# ISD9100_v3 register map
File version: 1.0
Registers are 32-bit, read-write, reset 0x0 unless marked. A register's access mark holds for its fields unless they carry their own. Offsets are from the block's base; [hi:lo] are bit positions.

## WDT — WDT Register Map
Base 0x40004000
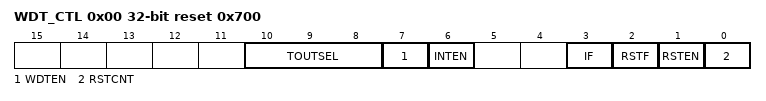
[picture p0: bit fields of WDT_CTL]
0x00 WDT_CTL reset 0x700 — Watchdog Timer Control Register
  [10:8] TOUTSEL — Watchdog Timer Interval Select. These three bits select the timeout interval for the Watchdog timer, a watchdog reset will occur 1024 clock cycles later if WDG not reset. The timeout is given by: Interrupt Timeout aaa 2^(2xWTIS+4) x WDT_CLK. Reset Timeout aaa (2^(2xWTIS+4) +1024) x WDT_CLK. Where WDT_CLK is the period of the Watchdog Timer clock source.
  [7] WDTEN — Watchdog Timer Enable
    0=Disable the Watchdog timer (This action will reset the internal counter); 1=Enable the Watchdog timer
  [6] INTEN — Watchdog Timer Interrupt Enable
    0=Disable the Watchdog timer interrupt; 1=Enable the Watchdog timer interrupt
  [3] IF — Watchdog Timer Interrupt Flag. If the Watchdog timer interrupt is enabled, then the hardware will set this bit to indicate that the Watchdog timer interrupt has occurred. If the Watchdog timer interrupt is not enabled, then this bit indicates that a timeout period has elapsed. NOTE: This bit is cleared by writing 1 to this bit.
    0=Watchdog timer interrupt has not occurred; 1=Watchdog timer interrupt has occurred
  [2] RSTF — Watchdog Timer Reset Flag. When the Watchdog timer initiates a reset, the hardware will set this bit. This flag can be read by software to determine the source of reset. Software is responsible to clear it manually by writing 1 to it. If RSTEN is disabled, then the Watchdog timer has no effect on this bit. NOTE: This bit is cleared by writing 1 to this bit.
    0=Watchdog timer reset has not occurred; 1=Watchdog timer reset has occurred
  [1] RSTEN — Watchdog Timer Reset Enable. Setting this bit will enable the Watchdog timer reset function.
    0=Disable Watchdog timer reset function; 1=Enable Watchdog timer reset function
  [0] RSTCNT — Clear Watchdog Timer. Set this bit will clear the Watchdog timer. NOTE: This bit will auto clear after few clock cycle
    0=Writing 0 to this bit has no effect; 1=Reset the contents of the Watchdog timer

## CRC — CRC Register Map
Base 0x40090000
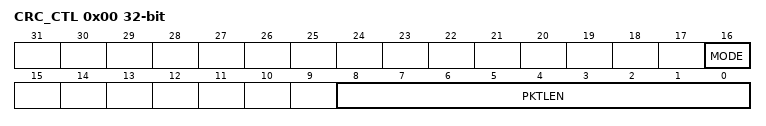
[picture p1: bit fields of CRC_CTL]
0x00 CRC_CTL — CRC Enable Control Register
  [16] MODE — CRC LSB mode. Determines whether CRC Generator processes input words (32bit/4Bytes) LSB (least significant byte) first or MSB (most significant byte) first. For example if MODE aaa 1, and 0x01020304 is written to CRC_DAT, bytes will be processed in order 0x04, 0x03, 0x02, 0x01. If MODE aaa 0, then order would be 0x01, 0x02, 0x3, 0x04. Writing any value to this register will flush all previous calculations and restart a new CRC calculation.
    0=CRC input is MSB first (default); 1=CRC input is LSB first
  [8:0] PKTLEN — CRC Packet Length. Indicates number of bytes of CRC input to process. CRC calculation will stop once input number of bytes aaa PKTLEN+1. Maximum packet size is 512 bytes, for PKTLEN aaa 511. Writing any value to this register will flush all previous calculations and restart a new CRC calculation.
0x04 CRC_DAT — CRC Input Register
  [31:0] DATA — CRC Input. The string of bytes to perform CRC calculation on. When MODE aaa 0, CRC performs calculation byte by byte in the order DATA[31:24], DATA[23:16], DATA[15:8], DATA[7:0]. When MODE aaa 1, CRC performs calculation byte by byte in the order DATA[7:0], DATA[15:8], DATA[23:16], DATA[31:24]. If number of input bytes exceeds CRC Packet Length (CRC_CTL[8:0]+1), any additional input bytes will be ignored. The CRC generator takes four clock cycles to process the CRC input. Software must ensure that at least four clock cycles occur between writes of CRC_DAT. Compiled assembly language can be examined to ensure this requirement is met.
0x08 CRC_CHECKSUM ro reset 0xFFFF — CRC Output Register
  [15:0] CHECKSUM — CRC Output. The result of CRC computation. The result is valid four clock cycles after last CRC_DAT input data is written to CRC generator.
